AUTOSAR XML (schema 00051)
package /Composition_Lab
  sender receiver interface SRI_LightControl
    data LightControl: type=uint32
  sender receiver interface SRI_LightActuate
    data LightActuate: type=uint32
  sensor actuator sw component type LightControlStatus_SWC
    provide port SR_PP_LightControl: provided-interface=SRI_LightControl
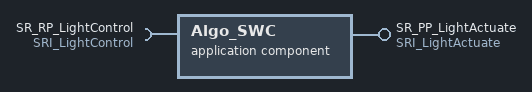
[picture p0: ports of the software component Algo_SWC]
  application sw component type Algo_SWC
    require port SR_RP_LightControl: required-interface=SRI_LightControl
    provide port SR_PP_LightActuate: provided-interface=SRI_LightActuate
  sensor actuator sw component type LightActuate_SWC
    require port SR_RP_LightActuate: required-interface=SRI_LightActuate
  composition sw component type SW_Composite1
    provide port SR_PP_LightActuate_Comp1: provided-interface=SRI_LightActuate
    component LightControl_SAC_SWC1: type=LightControlStatus_SWC
    component Algo_APP_SWC2: type=Algo_SWC
    connect LightControl_SAC_SWC1.SR_PP_LightControl -> Algo_APP_SWC2.SR_RP_LightControl
    delegate Algo_APP_SWC2.SR_PP_LightActuate <-> outer port SR_PP_LightActuate_Comp1
  composition sw component type TopLevel_Composite
    component SW_Composite1_SWC: type=SW_Composite1
    component LightActuate_SAC_SWC: type=LightActuate_SWC
    connect SW_Composite1_SWC.SR_PP_LightActuate_Comp1 -> LightActuate_SAC_SWC.SR_RP_LightActuate
